VERSION ""

NS_ :

BS_:

BU_:
VAL_TABLE_ ClusterWarning 1 "OneActiveBatteryWithError" 0 "OneBatteryInPermanentFail" ;
VAL_TABLE_ ClusterError 1024 "WrongClusterID" 512 "Critical Error" 256 "Precharge Error" ;
VAL_TABLE_ ClusterStateCnf 8 "Deepsleep" 2 "Charge" 1 "Discharge" 0 "Inactive" ;
VAL_TABLE_ ClusterStateReq 128 "Reset Idle Timeout" 8 "DeepSleep" 4 "Enter Alarm" 2 "Charge" 1 "Discharge" 0 "Inactive" ;

BO_ 3221225472 VECTOR__INDEPENDENT_SIG_MSG: 0 Vector__XXX
 SG_ NoActiveOrIdleBatteries : 0|1@1- (1,0) [0|0] "" Vector__XXX

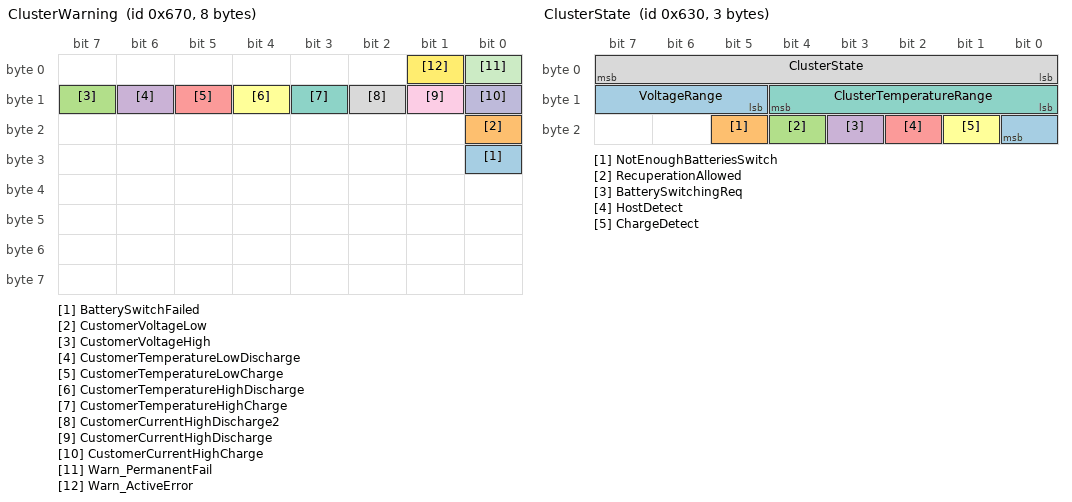
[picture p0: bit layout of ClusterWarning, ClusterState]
BO_ 1648 ClusterWarning: 8 Vector__XXX
 SG_ BatterySwitchFailed : 24|1@1- (1,0) [0|0] "" Vector__XXX
 SG_ CustomerVoltageLow : 16|1@1- (1,0) [0|0] "V" Vector__XXX
 SG_ CustomerVoltageHigh : 15|1@1- (1,0) [0|0] "V" Vector__XXX
 SG_ CustomerTemperatureLowDischarge : 14|1@1- (1,0) [0|0] "A" Vector__XXX
 SG_ CustomerTemperatureLowCharge : 13|1@1- (1,0) [0|0] "A" Vector__XXX
 SG_ CustomerTemperatureHighDischarge : 12|1@1- (1,0) [0|0] "A" Vector__XXX
 SG_ CustomerTemperatureHighCharge : 11|1@1- (1,0) [0|0] "A" Vector__XXX
 SG_ CustomerCurrentHighDischarge2 : 10|1@1- (1,0) [0|0] "A" Vector__XXX
 SG_ CustomerCurrentHighDischarge : 9|1@1- (1,0) [0|0] "A" Vector__XXX
 SG_ CustomerCurrentHighCharge : 8|1@1- (1,0) [0|0] "A" Vector__XXX
 SG_ Warn_PermanentFail : 0|1@1- (1,0) [0|0] "" Vector__XXX
 SG_ Warn_ActiveError : 1|1@1- (1,0) [0|0] "" Vector__XXX

BO_ 1632 ClusterError: 8 Vector__XXX
 SG_ BatteryErrorFlagDetected : 12|1@1- (1,0) [0|0] "" Vector__XXX
 SG_ NotEnoughBatteriesSwitch : 14|1@1- (1,0) [0|0] "" Vector__XXX
 SG_ MissingHeartbeat : 13|1@1- (1,0) [0|0] "" Vector__XXX
 SG_ RAMError : 28|1@1- (1,0) [0|0] "" Vector__XXX
 SG_ VoltageMismatchError : 5|1@1- (1,0) [0|0] "" Vector__XXX
 SG_ UnbalancedCurrent : 4|1@1- (1,0) [0|0] "" Vector__XXX
 SG_ HostDetectNotPlausible : 24|1@1- (1,0) [0|0] "" Vector__XXX
 SG_ FlashError : 29|1@1- (1,0) [0|0] "" Vector__XXX
 SG_ EEPROMError : 30|1@1- (1,0) [0|0] "" Vector__XXX
 SG_ ChargeDetectNotPlausible : 25|1@1- (1,0) [0|0] "" Vector__XXX
 SG_ BatteryUndervoltageError : 3|1@1- (1,0) [0|0] "" Vector__XXX
 SG_ BatteryUnderTemperatureError : 1|1@1- (1,0) [0|0] "" Vector__XXX
 SG_ BatteryOvervoltageError : 2|1@1- (1,0) [0|0] "" Vector__XXX
 SG_ BatteryOvertemperatureError : 0|1@1- (1,0) [0|0] "" Vector__XXX
 SG_ Error_Wrong_ClusterID : 10|1@1- (1,0) [0|0] "" Vector__XXX
 SG_ Error_Precharge : 8|1@1- (1,0) [0|1] "" Vector__XXX
 SG_ Error_Critical : 9|1@1- (1,0) [0|0] "" Vector__XXX

BO_ 1616 ClusterTemperature: 2 Vector__XXX
 SG_ MinCellTemperature : 8|8@1- (1,0) [-50|150] "°C" Vector__XXX
 SG_ MaxCellTemperature : 0|8@1- (1,0) [-50|150] "°C" Vector__XXX

BO_ 1600 PowerPrediction: 6 Vector__XXX
 SG_ MaxDischargeCurrent : 0|24@1- (1,0) [-10000000|0] "mA" Vector__XXX
 SG_ MaxChargeCurrent : 24|24@1- (1,0) [0|4000000] "mA" Vector__XXX

BO_ 1584 ClusterState: 3 Vector__XXX
 SG_ VoltageRange : 13|4@1- (1,0) [0|0] "" Vector__XXX
 SG_ NotEnoughBatteriesSwitch : 21|1@1- (1,0) [0|0] "" Vector__XXX
 SG_ RecuperationAllowed : 20|1@1- (1,0) [0|0] "" Vector__XXX
 SG_ BatterySwitchingReq : 19|1@1- (1,0) [0|0] "" Vector__XXX
 SG_ HostDetect : 18|1@1- (1,0) [0|0] "" Vector__XXX
 SG_ ChargeDetect : 17|1@1- (1,0) [0|0] "" Vector__XXX
 SG_ ClusterTemperatureRange : 8|5@1- (1,0) [0|0] "" Vector__XXX
 SG_ ClusterState : 0|8@1- (1,0) [0|0] "" Vector__XXX

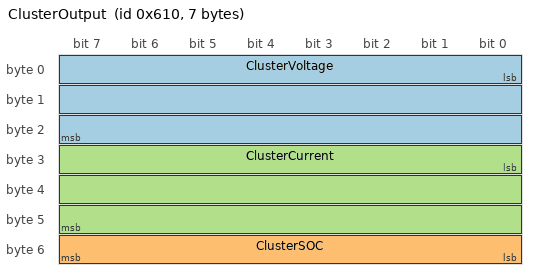
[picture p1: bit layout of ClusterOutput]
BO_ 1552 ClusterOutput: 7 Vector__XXX
 SG_ ClusterVoltage : 0|24@1+ (1,0) [0|16777215] "mV" Vector__XXX
 SG_ ClusterSOC : 48|8@1+ (1,0) [0|255] "%" Vector__XXX
 SG_ ClusterCurrent : 24|24@1- (1,0) [-10000000|4000000] "mA" Vector__XXX

BO_ 1536 ClusterControl: 2 Vector__XXX
 SG_ batterySwitchAck : 8|1@1- (1,0) [0|0] "" Vector__XXX
 SG_ stateReq : 0|8@1- (1,0) [0|0] "" Vector__XXX

CM_ BO_ 3221225472 "This is a message for not used signals, created by Vector CANdb++ DBC OLE DB Provider.";
CM_ SG_ 1632 NotEnoughBatteriesSwitch "The cluster does not have enough batteries to switch on as much batteries as defined in the cluster configuration
";
CM_ SG_ 1632 MissingHeartbeat "At least one battery did not reply to a heartbeat signal from the cluster manager
";
CM_ SG_ 1632 HostDetectNotPlausible "Host Detect not detected by all batteries
";
CM_ SG_ 1632 ChargeDetectNotPlausible "Charge Detect is not detected by all batteries";
CM_ SG_ 1584 NotEnoughBatteriesSwitch "The cluster does not have enough batteries to switch on as much batteries as defined in the cluster configuration
";
CM_ SG_ 1552 ClusterSOC "Average SOC of the active batteries";
VAL_ 1584 ClusterState 4 "Fault" 8 "Deepsleep" 2 "Charge" 1 "Discharge" 0 "Inactive" ;
VAL_ 1536 stateReq 128 "Reset Idle Timeout" 8 "DeepSleep" 4 "Enter Alarm" 2 "Charge" 1 "Discharge" 0 "Inactive" ;
